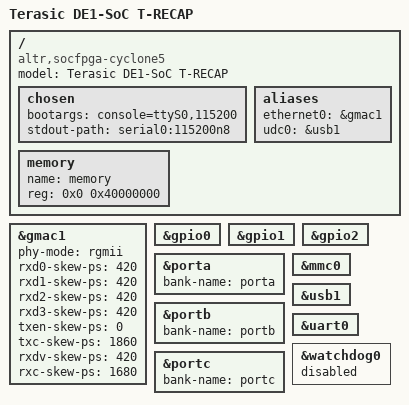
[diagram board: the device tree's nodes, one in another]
// SPDX-License-Identifier: GPL-2.0+
/*
 * Adapted for T-RECAP from U-Boot v2025.01 socfpga_cyclone5_de1_soc.dts.
 * Linux 6.12 owns peripheral clocks; the static T-RECAP include adds ring/GPIO ownership.
 * Copyright Altera Corporation (C) 2015
 */

#include "socfpga_cyclone5.dtsi"
#include "trecap_platform.dtsi"

/ {
	model = "Terasic DE1-SoC T-RECAP";
	compatible = "altr,socfpga-cyclone5", "altr,socfpga";

	chosen {
		bootargs = "console=ttyS0,115200";
		stdout-path = "serial0:115200n8";
	};

	aliases {
		ethernet0 = &gmac1;
		udc0 = &usb1;
	};

	memory {
		name = "memory";
		device_type = "memory";
		reg = <0x0 0x40000000>; /* 1GB */
	};
};

&gmac1 {
	status = "okay";
	phy-mode = "rgmii";

	rxd0-skew-ps = <420>;
	rxd1-skew-ps = <420>;
	rxd2-skew-ps = <420>;
	rxd3-skew-ps = <420>;
	txen-skew-ps = <0>;
	txc-skew-ps = <1860>;
	rxdv-skew-ps = <420>;
	rxc-skew-ps = <1680>;
};

&gpio0 {
	status = "okay";
};

&gpio1 {
	status = "okay";
};

&gpio2 {
	status = "okay";
};

&porta {
	bank-name = "porta";
};

&portb {
	bank-name = "portb";
};

&portc {
	bank-name = "portc";
};

&mmc0 {
	status = "okay";
};

&usb1 {
	status = "okay";
};

&uart0 {
};

&watchdog0 {
	status = "disabled";
};
